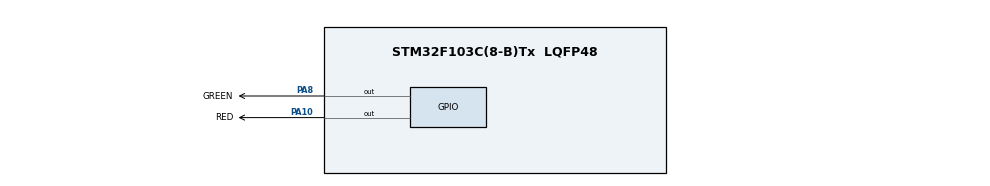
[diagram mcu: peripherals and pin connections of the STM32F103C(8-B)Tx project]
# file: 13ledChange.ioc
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FREERTOS.Queues01=myQueue01,16,uint16_t,0,Dynamic,NULL,NULL
FREERTOS.Tasks01=startREDTask,24,128,StartDefaultTask,Default,NULL,Dynamic,NULL,NULL;startGREENTask,8,128,StartTask02,Default,NULL,Dynamic,NULL,NULL
Mcu.Family=STM32F1
Mcu.Name=STM32F103C(8-B)Tx
Mcu.Package=LQFP48
NVIC.PriorityGroup=NVIC_PRIORITYGROUP_4
PA10.GPIO_Label=RED
PA10.Signal=GPIO_Output
PA13.Mode=Serial_Wire
PA13.Signal=SYS_JTMS-SWDIO
PA14.Mode=Serial_Wire
PA14.Signal=SYS_JTCK-SWCLK
PA8.GPIO_Label=GREEN
PA8.Signal=GPIO_Output
ProjectManager.HeapSize=0x200
ProjectManager.StackSize=0x400
ProjectManager.TargetToolchain=CMake
RCC.APB1Freq_Value=8000000
RCC.APB2Freq_Value=8000000
VP_FREERTOS_VS_CMSIS_V2.Mode=CMSIS_V2
board=custom

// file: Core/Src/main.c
/* USER CODE BEGIN Header */
/**
  ******************************************************************************
  * @file           : main.c
  * @brief          : Main program body
  ******************************************************************************
  * @attention
  *
  * Copyright (c) 2026 STMicroelectronics.
  * All rights reserved.
  *
  * This software is licensed under terms that can be found in the LICENSE file
  * in the root directory of this software component.
  * If no LICENSE file comes with this software, it is provided AS-IS.
  *
  ******************************************************************************
  */
/* USER CODE END Header */
#include "main.h"
#include "cmsis_os.h"
#include "cmsis_os2.h"
#include "stm32f1xx_hal_gpio.h"

/* Definitions for startREDTask */
osThreadId_t startREDTaskHandle;
const osThreadAttr_t startREDTask_attributes = {
  .name = "startREDTask",
  .stack_size = 128 * 4,
  .priority = (osPriority_t) osPriorityNormal,
};
/* Definitions for startGREENTask */
osThreadId_t startGREENTaskHandle;
const osThreadAttr_t startGREENTask_attributes = {
  .name = "startGREENTask",
  .stack_size = 128 * 4,
  .priority = (osPriority_t) osPriorityLow,
};
/* Definitions for myQueue01 */
osMessageQueueId_t myQueue01Handle;
const osMessageQueueAttr_t myQueue01_attributes = {
  .name = "myQueue01"
};

void SystemClock_Config(void);
static void MX_GPIO_Init(void);
void StartDefaultTask(void *argument);
void StartTask02(void *argument);

int main(void)
{

  /* MCU Configuration--------------------------------------------------------*/

  /* Reset of all peripherals, Initializes the Flash interface and the Systick. */
  HAL_Init();

  /* Configure the system clock */
  SystemClock_Config();

  /* Initialize all configured peripherals */
  MX_GPIO_Init();

  /* Init scheduler */
  osKernelInitialize();

  /* Create the queue(s) */
  /* creation of myQueue01 */
  myQueue01Handle = osMessageQueueNew (16, sizeof(uint16_t), &myQueue01_attributes);

  /* Create the thread(s) */
  /* creation of startREDTask */
  startREDTaskHandle = osThreadNew(StartDefaultTask, NULL, &startREDTask_attributes);

  /* creation of startGREENTask */
  startGREENTaskHandle = osThreadNew(StartTask02, NULL, &startGREENTask_attributes);

  /* Start scheduler */
  osKernelStart();

  /* We should never get here as control is now taken by the scheduler */

  /* Infinite loop */
  while (1)
  {

  }
}

void SystemClock_Config(void)
{
  RCC_OscInitTypeDef RCC_OscInitStruct = {0};
  RCC_ClkInitTypeDef RCC_ClkInitStruct = {0};

  /** Initializes the RCC Oscillators according to the specified parameters
  * in the RCC_OscInitTypeDef structure.
  */
  RCC_OscInitStruct.OscillatorType = RCC_OSCILLATORTYPE_HSI;
  RCC_OscInitStruct.HSIState = RCC_HSI_ON;
  RCC_OscInitStruct.HSICalibrationValue = RCC_HSICALIBRATION_DEFAULT;
  RCC_OscInitStruct.PLL.PLLState = RCC_PLL_NONE;
  if (HAL_RCC_OscConfig(&RCC_OscInitStruct) != HAL_OK)
  {
    Error_Handler();
  }

  /** Initializes the CPU, AHB and APB buses clocks
  */
  RCC_ClkInitStruct.ClockType = RCC_CLOCKTYPE_HCLK|RCC_CLOCKTYPE_SYSCLK
                              |RCC_CLOCKTYPE_PCLK1|RCC_CLOCKTYPE_PCLK2;
  RCC_ClkInitStruct.SYSCLKSource = RCC_SYSCLKSOURCE_HSI;
  RCC_ClkInitStruct.AHBCLKDivider = RCC_SYSCLK_DIV1;
  RCC_ClkInitStruct.APB1CLKDivider = RCC_HCLK_DIV1;
  RCC_ClkInitStruct.APB2CLKDivider = RCC_HCLK_DIV1;

  if (HAL_RCC_ClockConfig(&RCC_ClkInitStruct, FLASH_LATENCY_0) != HAL_OK)
  {
    Error_Handler();
  }
}

static void MX_GPIO_Init(void)
{
  GPIO_InitTypeDef GPIO_InitStruct = {0};

  /* GPIO Ports Clock Enable */
  __HAL_RCC_GPIOA_CLK_ENABLE();

  /*Configure GPIO pin Output Level */
  HAL_GPIO_WritePin(GPIOA, GREEN_Pin|RED_Pin, GPIO_PIN_RESET);

  /*Configure GPIO pins : GREEN_Pin RED_Pin */
  GPIO_InitStruct.Pin = GREEN_Pin|RED_Pin;
  GPIO_InitStruct.Mode = GPIO_MODE_OUTPUT_PP;
  GPIO_InitStruct.Pull = GPIO_NOPULL;
  GPIO_InitStruct.Speed = GPIO_SPEED_FREQ_LOW;
  HAL_GPIO_Init(GPIOA, &GPIO_InitStruct);

}

void StartDefaultTask(void *argument)
{
  /* USER CODE BEGIN 5 */
  /* Infinite loop */
  for(;;)
  {
    //红色小灯闪烁
    HAL_GPIO_TogglePin(RED_GPIO_Port, RED_Pin);
    osDelay(200);
  }
  /* USER CODE END 5 */
}

void StartTask02(void *argument)
{
  /* USER CODE BEGIN StartTask02 */
  /* Infinite loop */
  for(;;)
  {
    //绿色小灯闪烁
    for(int i = 0;i <= 5;i++)
    {
      HAL_GPIO_TogglePin(GREEN_GPIO_Port, GREEN_Pin);
      osDelay(200);
      HAL_GPIO_TogglePin(GREEN_GPIO_Port, GREEN_Pin);
      osDelay(200);
    }
    osDelay(500);
  }
  /* USER CODE END StartTask02 */
}

void Error_Handler(void)
{
  __disable_irq();
  while (1)
  {
  }
}
